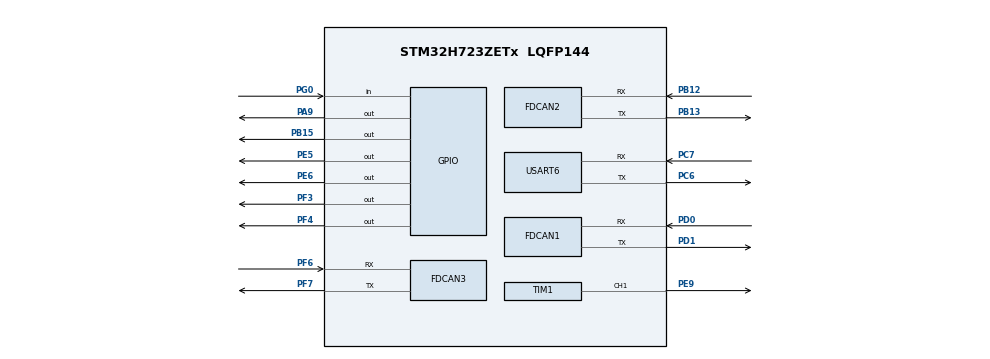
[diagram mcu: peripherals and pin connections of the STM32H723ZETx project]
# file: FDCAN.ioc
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CORTEX_M7.default_mode_Activation=1
Dma.Request0=USART6_TX
Dma.Request1=USART6_RX
Dma.USART6_RX.1.Direction=DMA_PERIPH_TO_MEMORY
Dma.USART6_RX.1.EventEnable=DISABLE
Dma.USART6_RX.1.FIFOMode=DMA_FIFOMODE_DISABLE
Dma.USART6_RX.1.Instance=DMA1_Stream1
Dma.USART6_RX.1.MemDataAlignment=DMA_MDATAALIGN_BYTE
Dma.USART6_RX.1.MemInc=DMA_MINC_ENABLE
Dma.USART6_RX.1.Mode=DMA_NORMAL
Dma.USART6_RX.1.PeriphDataAlignment=DMA_PDATAALIGN_BYTE
Dma.USART6_RX.1.PeriphInc=DMA_PINC_DISABLE
Dma.USART6_RX.1.Polarity=HAL_DMAMUX_REQ_GEN_RISING
Dma.USART6_RX.1.Priority=DMA_PRIORITY_MEDIUM
Dma.USART6_RX.1.RequestNumber=1
Dma.USART6_RX.1.SignalID=NONE
Dma.USART6_RX.1.SyncEnable=DISABLE
Dma.USART6_RX.1.SyncPolarity=HAL_DMAMUX_SYNC_NO_EVENT
Dma.USART6_RX.1.SyncRequestNumber=1
Dma.USART6_RX.1.SyncSignalID=NONE
Dma.USART6_TX.0.Direction=DMA_MEMORY_TO_PERIPH
Dma.USART6_TX.0.EventEnable=DISABLE
Dma.USART6_TX.0.FIFOMode=DMA_FIFOMODE_DISABLE
Dma.USART6_TX.0.Instance=DMA1_Stream0
Dma.USART6_TX.0.MemDataAlignment=DMA_MDATAALIGN_BYTE
Dma.USART6_TX.0.MemInc=DMA_MINC_ENABLE
Dma.USART6_TX.0.Mode=DMA_NORMAL
Dma.USART6_TX.0.PeriphDataAlignment=DMA_PDATAALIGN_BYTE
Dma.USART6_TX.0.PeriphInc=DMA_PINC_DISABLE
Dma.USART6_TX.0.Polarity=HAL_DMAMUX_REQ_GEN_RISING
Dma.USART6_TX.0.Priority=DMA_PRIORITY_MEDIUM
Dma.USART6_TX.0.RequestNumber=1
Dma.USART6_TX.0.SignalID=NONE
Dma.USART6_TX.0.SyncEnable=DISABLE
Dma.USART6_TX.0.SyncPolarity=HAL_DMAMUX_SYNC_NO_EVENT
Dma.USART6_TX.0.SyncRequestNumber=1
Dma.USART6_TX.0.SyncSignalID=NONE
FDCAN1.CalculateBaudRateNominal=1000000
FDCAN1.CalculateTimeBitNominal=1000
FDCAN1.CalculateTimeQuantumNominal=25.0
FDCAN1.DataPrescaler=3
FDCAN1.DataSyncJumpWidth=10
FDCAN1.DataTimeSeg1=29
FDCAN1.DataTimeSeg2=10
FDCAN1.NominalPrescaler=3
FDCAN1.NominalSyncJumpWidth=10
FDCAN1.NominalTimeSeg1=29
FDCAN1.NominalTimeSeg2=10
FDCAN1.ProtocolException=ENABLE
FDCAN1.RxFifo0ElmtsNbr=4
FDCAN1.StdFiltersNbr=1
FDCAN1.TxFifoQueueElmtsNbr=4
FDCAN2.CalculateBaudRateNominal=1000000
FDCAN2.CalculateTimeBitNominal=1000
FDCAN2.CalculateTimeQuantumNominal=25.0
FDCAN2.DataPrescaler=3
FDCAN2.DataSyncJumpWidth=10
FDCAN2.DataTimeSeg1=29
FDCAN2.DataTimeSeg2=10
FDCAN2.NominalPrescaler=3
FDCAN2.NominalSyncJumpWidth=10
FDCAN2.NominalTimeSeg1=29
FDCAN2.NominalTimeSeg2=10
FDCAN2.ProtocolException=ENABLE
FDCAN2.RxFifo0ElmtsNbr=4
FDCAN2.StdFiltersNbr=1
FDCAN2.TxFifoQueueElmtsNbr=4
FDCAN3.CalculateBaudRateNominal=1000000
FDCAN3.CalculateTimeBitNominal=1000
FDCAN3.CalculateTimeQuantumNominal=25.0
FDCAN3.DataPrescaler=3
FDCAN3.DataSyncJumpWidth=10
FDCAN3.DataTimeSeg1=29
FDCAN3.DataTimeSeg2=10
FDCAN3.NominalPrescaler=3
FDCAN3.NominalSyncJumpWidth=10
FDCAN3.NominalTimeSeg1=29
FDCAN3.NominalTimeSeg2=10
FDCAN3.ProtocolException=ENABLE
FDCAN3.RxFifo0ElmtsNbr=4
FDCAN3.StdFiltersNbr=1
FDCAN3.TxFifoQueueElmtsNbr=4
FREERTOS.Tasks01=Raise_Task,24,256,Raise_task,As weak,NULL,Dynamic,NULL,NULL;LEG_task,24,512,leg_task,As weak,NULL,Dynamic,NULL,NULL
Mcu.Family=STM32H7
Mcu.Name=STM32H723ZETx
Mcu.Package=LQFP144
NVIC.DMA1_Stream0_IRQn=true\:5\:0\:false\:false\:true\:true\:false\:true\:true
NVIC.DMA1_Stream1_IRQn=true\:5\:0\:false\:false\:true\:true\:false\:true\:true
NVIC.FDCAN1_IT0_IRQn=true\:5\:0\:false\:false\:true\:true\:true\:true\:true
NVIC.FDCAN1_IT1_IRQn=true\:5\:0\:false\:false\:true\:true\:true\:true\:true
NVIC.FDCAN3_IT0_IRQn=true\:5\:0\:false\:false\:true\:true\:true\:true\:true
NVIC.FDCAN_CAL_IRQn=true\:5\:0\:false\:false\:true\:true\:true\:true\:true
NVIC.PriorityGroup=NVIC_PRIORITYGROUP_4
NVIC.TIM2_IRQn=true\:15\:0\:false\:false\:true\:false\:false\:true\:true
NVIC.TimeBase=TIM2_IRQn
NVIC.TimeBaseIP=TIM2
NVIC.USART6_IRQn=true\:5\:0\:false\:false\:true\:true\:true\:true\:true
PA13(JTMS/SWDIO).Mode=Serial_Wire
PA13(JTMS/SWDIO).Signal=DEBUG_JTMS-SWDIO
PA14(JTCK/SWCLK).Mode=Serial_Wire
PA14(JTCK/SWCLK).Signal=DEBUG_JTCK-SWCLK
PA9.Signal=GPIO_Output
PB12.Mode=FDCAN_Activate
PB12.Signal=FDCAN2_RX
PB13.Mode=FDCAN_Activate
PB13.Signal=FDCAN2_TX
PB15.Signal=GPIO_Output
PC6.Mode=Asynchronous
PC6.Signal=USART6_TX
PC7.Mode=Asynchronous
PC7.Signal=USART6_RX
PD0.GPIO_PuPd=GPIO_PULLUP
PD0.GPIO_Speed=GPIO_SPEED_FREQ_HIGH
PD0.Mode=FDCAN_Activate
PD0.Signal=FDCAN1_RX
PD1.GPIO_PuPd=GPIO_PULLUP
PD1.Mode=FDCAN_Activate
PD1.Signal=FDCAN1_TX
PE5.Signal=GPIO_Output
PE6.Signal=GPIO_Output
PE9.Signal=S_TIM1_CH1
PF3.Signal=GPIO_Output
PF4.Signal=GPIO_Output
PF6.GPIO_Speed=GPIO_SPEED_FREQ_HIGH
PF6.Mode=FDCAN_Activate
PF6.Signal=FDCAN3_RX
PF7.Mode=FDCAN_Activate
PF7.Signal=FDCAN3_TX
PG0.GPIO_PuPd=GPIO_PULLUP
PG0.Signal=GPIO_Input
PH0-OSC_IN.Mode=HSE-External-Oscillator
PH0-OSC_IN.Signal=RCC_OSC_IN
PH1-OSC_OUT.Mode=HSE-External-Oscillator
PH1-OSC_OUT.Signal=RCC_OSC_OUT
ProjectManager.HeapSize=0x200
ProjectManager.StackSize=0x400
ProjectManager.TargetToolchain=MDK-ARM V5.32
RCC.ADCFreq_Value=50390625
RCC.APB1Freq_Value=120000000
RCC.APB2Freq_Value=120000000
RCC.APB3Freq_Value=120000000
RCC.APB4Freq_Value=120000000
RCC.CortexFreq_Value=480000000
RCC.D1PPRE=RCC_APB3_DIV2
RCC.D2PPRE1=RCC_APB1_DIV2
RCC.D2PPRE2=RCC_APB2_DIV2
RCC.D3PPRE=RCC_APB4_DIV2
RCC.DIVM1=5
RCC.DIVN1=96
RCC.DIVP1=1
RCC.DIVQ1=4
RCC.HCLKFreq_Value=240000000
RCC.HPRE=RCC_HCLK_DIV2
RCC.HSE_VALUE=25000000
RCC.PLL2FRACN=0
RCC.PLL3FRACN=0
RCC.PLLFRACN=0
RCC.PLLSourceVirtual=RCC_PLLSOURCE_HSE
RCC.SYSCLKFreq_VALUE=480000000
RCC.SYSCLKSource=RCC_SYSCLKSOURCE_PLLCLK
RCC.USBFreq_Value=120000000
SH.S_TIM1_CH1.0=TIM1_CH1,PWM Generation1 CH1
STMicroelectronics.X-CUBE-ALGOBUILD.1.4.0.LibraryCcDSPOoLibraryJjDSPOoLibrary=true
TIM1.Channel-PWM\ Generation1\ CH1=TIM_CHANNEL_1
TIM1.Period=1999
TIM1.Prescaler=2399
USART6.VirtualMode-Asynchronous=VM_ASYNC
VP_FREERTOS_VS_CMSIS_V2.Mode=CMSIS_V2
VP_MEMORYMAP_VS_MEMORYMAP.Mode=CurAppReg
VP_STMicroelectronics.X-CUBE-ALGOBUILD_VS_DSPOoLibraryJjLibrary_1.4.0_1.4.0.Mode=DSPOoLibraryJjLibrary
VP_SYS_VS_tim2.Mode=TIM2
VP_TIM1_VS_ClockSourceINT.Mode=Internal
board=custom

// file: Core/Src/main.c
/* USER CODE BEGIN Header */
/**
  ******************************************************************************
  * @file           : main.c
  * @brief          : Main program body
  ******************************************************************************
  * @attention
  *
  * Copyright (c) 2025 STMicroelectronics.
  * All rights reserved.
  *
  * This software is licensed under terms that can be found in the LICENSE file
  * in the root directory of this software component.
  * If no LICENSE file comes with this software, it is provided AS-IS.
  *
  ******************************************************************************
  */
/* USER CODE END Header */
#include "main.h"
#include "cmsis_os.h"
#include "dma.h"
#include "fdcan.h"
#include "tim.h"
#include "usart.h"
#include "gpio.h"

/* USER CODE BEGIN Includes */
#include "bsp_fdcan.h"
#include "3508_control.h"
#include "leg_task.h"
#include "relay.h"
#include "rc_protocol.h"
/* USER CODE END Includes */

/* USER CODE BEGIN PV */
extern motor_control control_3508_classic[5];
extern MotorRun motor_3508[4];
float e;
/* USER CODE END PV */

void SystemClock_Config(void);
static void MPU_Config(void);
void MX_FREERTOS_Init(void);

int main(void)
{

  /* MPU Configuration--------------------------------------------------------*/
  MPU_Config();

  /* MCU Configuration--------------------------------------------------------*/

  /* Reset of all peripherals, Initializes the Flash interface and the Systick. */
  HAL_Init();

  /* Configure the system clock */
  SystemClock_Config();

  /* Initialize all configured peripherals */
  MX_GPIO_Init();
  MX_DMA_Init();
  MX_FDCAN1_Init();
  MX_FDCAN2_Init();
  MX_FDCAN3_Init();
  MX_USART6_UART_Init();
  MX_TIM1_Init();
  /* USER CODE BEGIN 2 */
  rc_protocol_init();   /* RC串口通信初始化*/
  relay_init();       /* 继电器初始化: 两个电磁阀通电, 气缸缩回 */
  fdcan_config();
  /* USER CODE END 2 */

  /* Init scheduler */
  osKernelInitialize();  /* Call init function for freertos objects (in cmsis_os2.c) */
  MX_FREERTOS_Init();

  /* Start scheduler */
  osKernelStart();

  /* We should never get here as control is now taken by the scheduler */

  /* Infinite loop */
  while (1)
  {

  }
}

void SystemClock_Config(void)
{
  RCC_OscInitTypeDef RCC_OscInitStruct = {0};
  RCC_ClkInitTypeDef RCC_ClkInitStruct = {0};

  /** Supply configuration update enable
  */
  HAL_PWREx_ConfigSupply(PWR_LDO_SUPPLY);

  /** Configure the main internal regulator output voltage
  */
  __HAL_PWR_VOLTAGESCALING_CONFIG(PWR_REGULATOR_VOLTAGE_SCALE0);

  while(!__HAL_PWR_GET_FLAG(PWR_FLAG_VOSRDY)) {}

  /** Initializes the RCC Oscillators according to the specified parameters
  * in the RCC_OscInitTypeDef structure.
  */
  RCC_OscInitStruct.OscillatorType = RCC_OSCILLATORTYPE_HSE;
  RCC_OscInitStruct.HSEState = RCC_HSE_ON;
  RCC_OscInitStruct.PLL.PLLState = RCC_PLL_ON;
  RCC_OscInitStruct.PLL.PLLSource = RCC_PLLSOURCE_HSE;
  RCC_OscInitStruct.PLL.PLLM = 5;
  RCC_OscInitStruct.PLL.PLLN = 96;
  RCC_OscInitStruct.PLL.PLLP = 1;
  RCC_OscInitStruct.PLL.PLLQ = 4;
  RCC_OscInitStruct.PLL.PLLR = 2;
  RCC_OscInitStruct.PLL.PLLRGE = RCC_PLL1VCIRANGE_2;
  RCC_OscInitStruct.PLL.PLLVCOSEL = RCC_PLL1VCOWIDE;
  RCC_OscInitStruct.PLL.PLLFRACN = 0;
  if (HAL_RCC_OscConfig(&RCC_OscInitStruct) != HAL_OK)
  {
    Error_Handler();
  }

  /** Initializes the CPU, AHB and APB buses clocks
  */
  RCC_ClkInitStruct.ClockType = RCC_CLOCKTYPE_HCLK|RCC_CLOCKTYPE_SYSCLK
                              |RCC_CLOCKTYPE_PCLK1|RCC_CLOCKTYPE_PCLK2
                              |RCC_CLOCKTYPE_D3PCLK1|RCC_CLOCKTYPE_D1PCLK1;
  RCC_ClkInitStruct.SYSCLKSource = RCC_SYSCLKSOURCE_PLLCLK;
  RCC_ClkInitStruct.SYSCLKDivider = RCC_SYSCLK_DIV1;
  RCC_ClkInitStruct.AHBCLKDivider = RCC_HCLK_DIV2;
  RCC_ClkInitStruct.APB3CLKDivider = RCC_APB3_DIV2;
  RCC_ClkInitStruct.APB1CLKDivider = RCC_APB1_DIV2;
  RCC_ClkInitStruct.APB2CLKDivider = RCC_APB2_DIV2;
  RCC_ClkInitStruct.APB4CLKDivider = RCC_APB4_DIV2;

  if (HAL_RCC_ClockConfig(&RCC_ClkInitStruct, FLASH_LATENCY_3) != HAL_OK)
  {
    Error_Handler();
  }
}

 /* MPU Configuration */

void MPU_Config(void)
{
  MPU_Region_InitTypeDef MPU_InitStruct = {0};

  /* Disables the MPU */
  HAL_MPU_Disable();

  /** Initializes and configures the Region and the memory to be protected
  */
  MPU_InitStruct.Enable = MPU_REGION_ENABLE;
  MPU_InitStruct.Number = MPU_REGION_NUMBER0;
  MPU_InitStruct.BaseAddress = 0x0;
  MPU_InitStruct.Size = MPU_REGION_SIZE_4GB;
  MPU_InitStruct.SubRegionDisable = 0x87;
  MPU_InitStruct.TypeExtField = MPU_TEX_LEVEL0;
  MPU_InitStruct.AccessPermission = MPU_REGION_NO_ACCESS;
  MPU_InitStruct.DisableExec = MPU_INSTRUCTION_ACCESS_DISABLE;
  MPU_InitStruct.IsShareable = MPU_ACCESS_SHAREABLE;
  MPU_InitStruct.IsCacheable = MPU_ACCESS_NOT_CACHEABLE;
  MPU_InitStruct.IsBufferable = MPU_ACCESS_NOT_BUFFERABLE;

  HAL_MPU_ConfigRegion(&MPU_InitStruct);
  /* Enables the MPU */
  HAL_MPU_Enable(MPU_PRIVILEGED_DEFAULT);

}

void HAL_TIM_PeriodElapsedCallback(TIM_HandleTypeDef *htim)
{
  if (htim->Instance == TIM2)
  {
    HAL_IncTick();
  }
}

void Error_Handler(void)
{
  __disable_irq();
  while (1)
  {
  }
}

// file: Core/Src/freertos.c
/* USER CODE BEGIN Header */
/**
  ******************************************************************************
  * File Name          : freertos.c
  * Description        : Code for freertos applications
  ******************************************************************************
  * @attention
  *
  * Copyright (c) 2026 STMicroelectronics.
  * All rights reserved.
  *
  * This software is licensed under terms that can be found in the LICENSE file
  * in the root directory of this software component.
  * If no LICENSE file comes with this software, it is provided AS-IS.
  *
  ******************************************************************************
  */
/* USER CODE END Header */

#include "FreeRTOS.h"
#include "task.h"
#include "main.h"
#include "cmsis_os.h"

/* Definitions for Raise_Task */
osThreadId_t Raise_TaskHandle;
const osThreadAttr_t Raise_Task_attributes = {
  .name = "Raise_Task",
  .stack_size = 256 * 4,
  .priority = (osPriority_t) osPriorityNormal,
};
/* Definitions for LEG_task */
osThreadId_t LEG_taskHandle;
const osThreadAttr_t LEG_task_attributes = {
  .name = "LEG_task",
  .stack_size = 512 * 4,
  .priority = (osPriority_t) osPriorityNormal,
};

void Raise_task(void *argument);
void leg_task(void *argument);

void MX_FREERTOS_Init(void); /* (MISRA C 2004 rule 8.1) */

void MX_FREERTOS_Init(void) {

  /* Create the thread(s) */
  /* creation of Raise_Task */
  Raise_TaskHandle = osThreadNew(Raise_task, NULL, &Raise_Task_attributes);

  /* creation of LEG_task */
  LEG_taskHandle = osThreadNew(leg_task, NULL, &LEG_task_attributes);

}

__weak void Raise_task(void *argument)
{
  for(;;)
  {
    osDelay(1);
  }
}

__weak void leg_task(void *argument)
{
  for(;;)
  {
    osDelay(1);
  }
}
